# STM32H7RSxx register map
File version: 0.1
CPU: CM7 r0p1, little endian, MPU, FPU, 4 interrupt priority bits
Registers are 32-bit, read-write, reset 0x0 unless marked. A register's access mark holds for its fields unless they carry their own. Offsets are from the block's base; [hi:lo] are bit positions; {n}, {i} and the like mark numbered series; 'fields as' and 'values as' point back to an identical list.

## PWR — Power control
Base 0x58024800
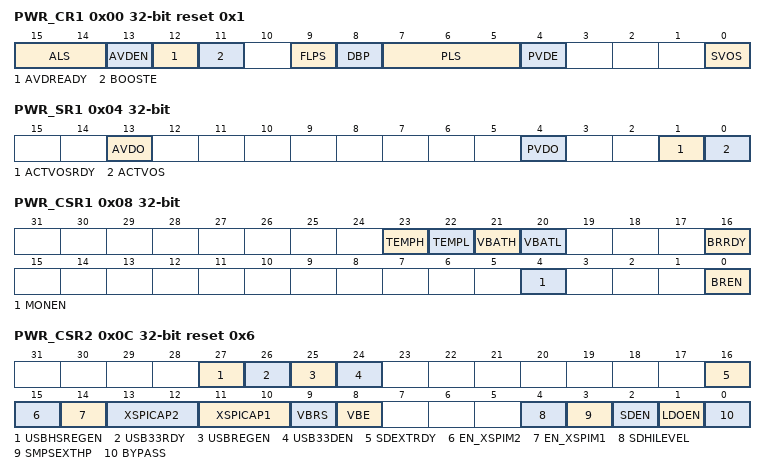
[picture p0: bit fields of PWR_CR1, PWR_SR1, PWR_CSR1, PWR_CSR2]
0x00 PWR_CR1 reset 0x1 — PWR control register 1
  [15:14] ALS — Analog voltage detector level selection
    {v}=AVD level {v+1} (v=0..3)
  [13] AVDEN — Analog voltage ready
    0=Peripheral voltage monitor on VDDA disabled; 1=Peripheral voltage monitor on VDDA enabled
  [12] AVDREADY — Analog voltage ready
    0=peripheral analog voltage VDDA not ready; 1=peripheral analog voltage VDDA ready
  [11] BOOSTE — Analog switch VBoost control
    0=booster disabled; 1=booster enabled if analog voltage ready (AVD_READY = 1)
  [9] FLPS — Flash low-power mode in Stop mode
    0=Flash memory remains in normal mode when device enters Stop; 1=Flash memory enters low-power mode when device enters Stop mode
  [8] DBP — Disable Backup domain write protection
    0=Write access to Backup domain disabled; 1=Write access to Backup domain enabled
  [7:5] PLS — Programmable voltage detector level selection
    {v}=PVD level {v+1} (v=0..6); 7=External input analog voltage PVD_IN (compared internally to VREFINT)
  [4] PVDE — Programmable voltage detector enable
    0=Programmable voltage detector disabled; 1=Programmable voltage detector enabled
  [0] SVOS — System Stop mode voltage scaling selection
    0=SVOS Low; 1=SVOS High
0x04 PWR_SR1 ro — PWR control status register 1
  [13] AVDO — Analog voltage detector output on VDDA
    0=VDDA is equal or higher than the AVD threshold selected with the ALS[1:0] bits; 1=VDDA is lower than the AVD threshold selected with the ALS[1:0] bits
  [4] PVDO — Programmable voltage detect output
    0=VDD or PVD_IN voltage is equal or higher than the PVD threshold selected through the PLS[2:0] bits; 1=VDD or PVD_IN voltage is lower than the PVD threshold selected through the PLS[2:0] bits
  [1] ACTVOSRDY — Voltage levels ready bit for currently used ACTVOS and SDHILEVEL
    0=Voltage level invalid, above or below current ACTVOS and SDHILEVEL selected levels; 1=Voltage level valid, at current ACTVOS and SDHILEVEL selected levels
  [0] ACTVOS — VOS currently applied for VCORE voltage scaling selection
0x08 PWR_CSR1 access per field — PWR control status register 1
  [23] TEMPH ro — Temperature level monitoring versus high threshold
    0=Temperature below high threshold level; 1=Temperature equal or above high threshold level
  [22] TEMPL ro — Temperature level monitoring versus low threshold
    0=Temperature above low threshold level; 1=Temperature equal or below low threshold level
  [21] VBATH ro — VBAT level monitoring versus high threshold
    0=VBAT level below high threshold level; 1=VBAT level equal or above high threshold level
  [20] VBATL ro — VBAT level monitoring versus low threshold
    0=VBAT level above low threshold level; 1=VBAT level equal or below low threshold level
  [16] BRRDY ro — Backup regulator ready
    0=Backup regulator not ready; 1=Backup regulator ready
  [4] MONEN rw — VBAT and temperature monitoring enable
    0=VBAT and temperature monitoring disabled; 1=VBAT and temperature monitoring enabled
  [0] BREN rw — Backup regulator enable
    0=Backup regulator disabled; 1=Backup regulator enabled
0x0C PWR_CSR2 access per field reset 0x6 — PWR control status register 2
  [27] USBHSREGEN rw — USB HS regulator enable
    0=USB HS PHY regulator disabled; 1=USB HS PHY regulator enabled
  [26] USB33RDY ro — USB supply ready
    0=USB33 supply not ready; 1=USB33 supply ready
  [25] USBREGEN rw — USB regulator enable
    0=USB regulator disabled; 1=USB regulator enabled
  [24] USB33DEN rw — VDD33_USB voltage level detector enable
    0=VDD33_USB voltage level detector disabled; 1=VDD33_USB voltage level detector enabled
  [16] SDEXTRDY ro — SMPS step-down converter external supply ready
    0=External supply not ready; 1=External supply ready
  [15] EN_XSPIM2 rw — allows the SW to enable the XSPI interface 2
    0=XSPIM2 interface is not enabled; 1=XSPIM2 interface is enabled
  [14] EN_XSPIM1 rw — allows the SW to enable the XSPI interface 1
    0=XSPIM1 interface is not enabled; 1=XSPIM1 interface is enabled
  [13:12] XSPICAP2 rw — XSPI port 2 capacitor control bits
    0=XSPI Capacitor OFF; 1=XSPI Capacitor set to 1/3; 2=XSPI Capacitor set to 2/3; 3=XSPI Capacitor set to full capacitance
  [11:10] XSPICAP1 rw — XSPI port 1 capacitor control bits
    values as XSPICAP2
  [9] VBRS rw — VBAT charging resistor selection
    0=Charge VBAT through a 5 kΩ resistor; 1=Charge VBAT through a 1.5 kΩ resistor
  [8] VBE rw — VBAT charging enable
    0=VBAT battery charging disabled; 1=VBAT battery charging enabled
  [4] SDHILEVEL rw — SMPS step-down converter voltage output for LDO or external supply
    0=Reset value; 1=1.8V
  [3] SMPSEXTHP rw — SMPS external power delivery selection
    0=SMPS normal operating mode, no power delivery to external circuits; 1=SMPS external operating mode, power delivery to external circuits
  [2] SDEN rw — SMPS step-down converter enable
    0=SMPS step-down converter disabled; 1=SMPS step-down converter enabled
  [1] LDOEN rw — Low drop-out regulator enable
    0=Low drop-out regulator disabled; 1=Low drop-out regulator enabled
  [0] BYPASS rw — Power management unit bypass
    0=Power management unit normal operation; 1=Power management unit bypassed, voltage monitoring still active
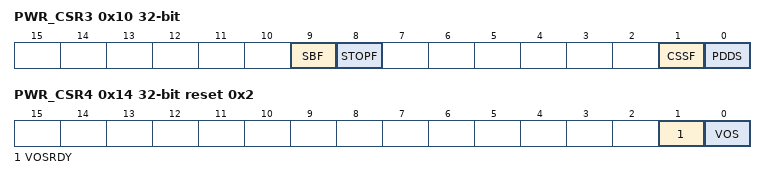
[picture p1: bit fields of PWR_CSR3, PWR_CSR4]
0x10 PWR_CSR3 access per field — PWR control status register 3
  [9] SBF ro — Standby flag
    0=System has not been in Standby mode; 1=System has been in Standby mode
  [8] STOPF ro — Stop flag
    0=System has not been in Stop mode; 1=System has been in Stop mode
  [1] CSSF wo — Clear Standby and Stop flags (always read as 0)
  [0] PDDS rw — Power Down Deepsleep
    0=Stop mode when device enters Deepsleep; 1=Standby mode when device enters Deepsleep
0x14 PWR_CSR4 access per field reset 0x2 — PWR control status register 4
  [1] VOSRDY ro — VOS Ready bit for VCORE voltage scaling output selection
    0=Not ready, voltage level below VOS selected level; 1=Ready, voltage level at or above VOS selected level
  [0] VOS rw — Voltage scaling selection according to performance
    0=VOS Low level; 1=VOS High level
0x20 PWR_WKUPCR access not given — PWR wakeup clear register
0x24 PWR_WKUPFR access not given — PWR wakeup flag register
0x28 PWR_WKUPEPR access not given — PWR wakeup enable and polarity register
0x28 PWR_WKUPEPR access not given — PWR wakeup enable and polarity register
0x2C PWR_UCPDR access not given reset 0x2 — PWR USB Type-C and Power Delivery register
0x30 PWR_APCR access not given reset 0x30000 — PWR apply pull configuration register
0x34 PWR_PUCRN access not given — PWR port N pull-up control register
0x38 PWR_PDCRN access not given — PWR port N pull-down control register
0x3C PWR_PUCRO access not given — PWR port O pull-up control register
0x40 PWR_PDCRO access not given — PWR port O pull-down control register
0x44 PWR_PDCRP access not given — PWR port P pull-down control register
